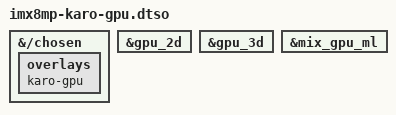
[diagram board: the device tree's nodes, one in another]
// SPDX-License-Identifier: (GPL-2.0 OR BSD-3-Clause)
/*
 * Copyright (C) 2022 Lothar Waßmann <LW@KARO-electronics.de>
 */

/dts-v1/;
/plugin/;

&{/chosen} {
	overlays {
		karo-gpu;
	};
};

&gpu_2d {
	status = "okay";
};

&gpu_3d {
	status = "okay";
};

&mix_gpu_ml {
	status = "okay";
};
